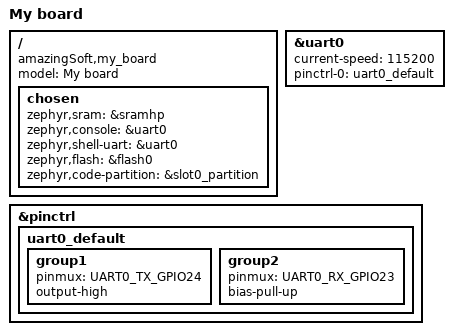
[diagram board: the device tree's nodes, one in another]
/dts-v1/;

#include <espressif/esp32h2/esp32h2_mini_h4.dtsi>
#include <espressif/partitions_0x0_default.dtsi>

#include <zephyr/dt-bindings/pinctrl/esp-pinctrl-common.h>
#include <dt-bindings/pinctrl/esp32h2-pinctrl.h>
#include <zephyr/dt-bindings/pinctrl/esp32h2-gpio-sigmap.h>

/ {
	model = "My board";
	compatible = "amazingSoft,my_board";

	chosen {
		zephyr,sram = &sramhp;
		zephyr,console = &uart0;
		zephyr,shell-uart = &uart0;
		zephyr,flash = &flash0;
		zephyr,code-partition = &slot0_partition;
    };
};

&uart0 {
	status = "okay";
	current-speed = <115200>;
	pinctrl-0 = <&uart0_default>;
	pinctrl-names = "default";
};

&pinctrl {
	uart0_default: uart0_default {
		group1 {
			pinmux = <UART0_TX_GPIO24>;
			output-high;
		};

		group2 {
			pinmux = <UART0_RX_GPIO23>;
			bias-pull-up;
		};
	};
};
